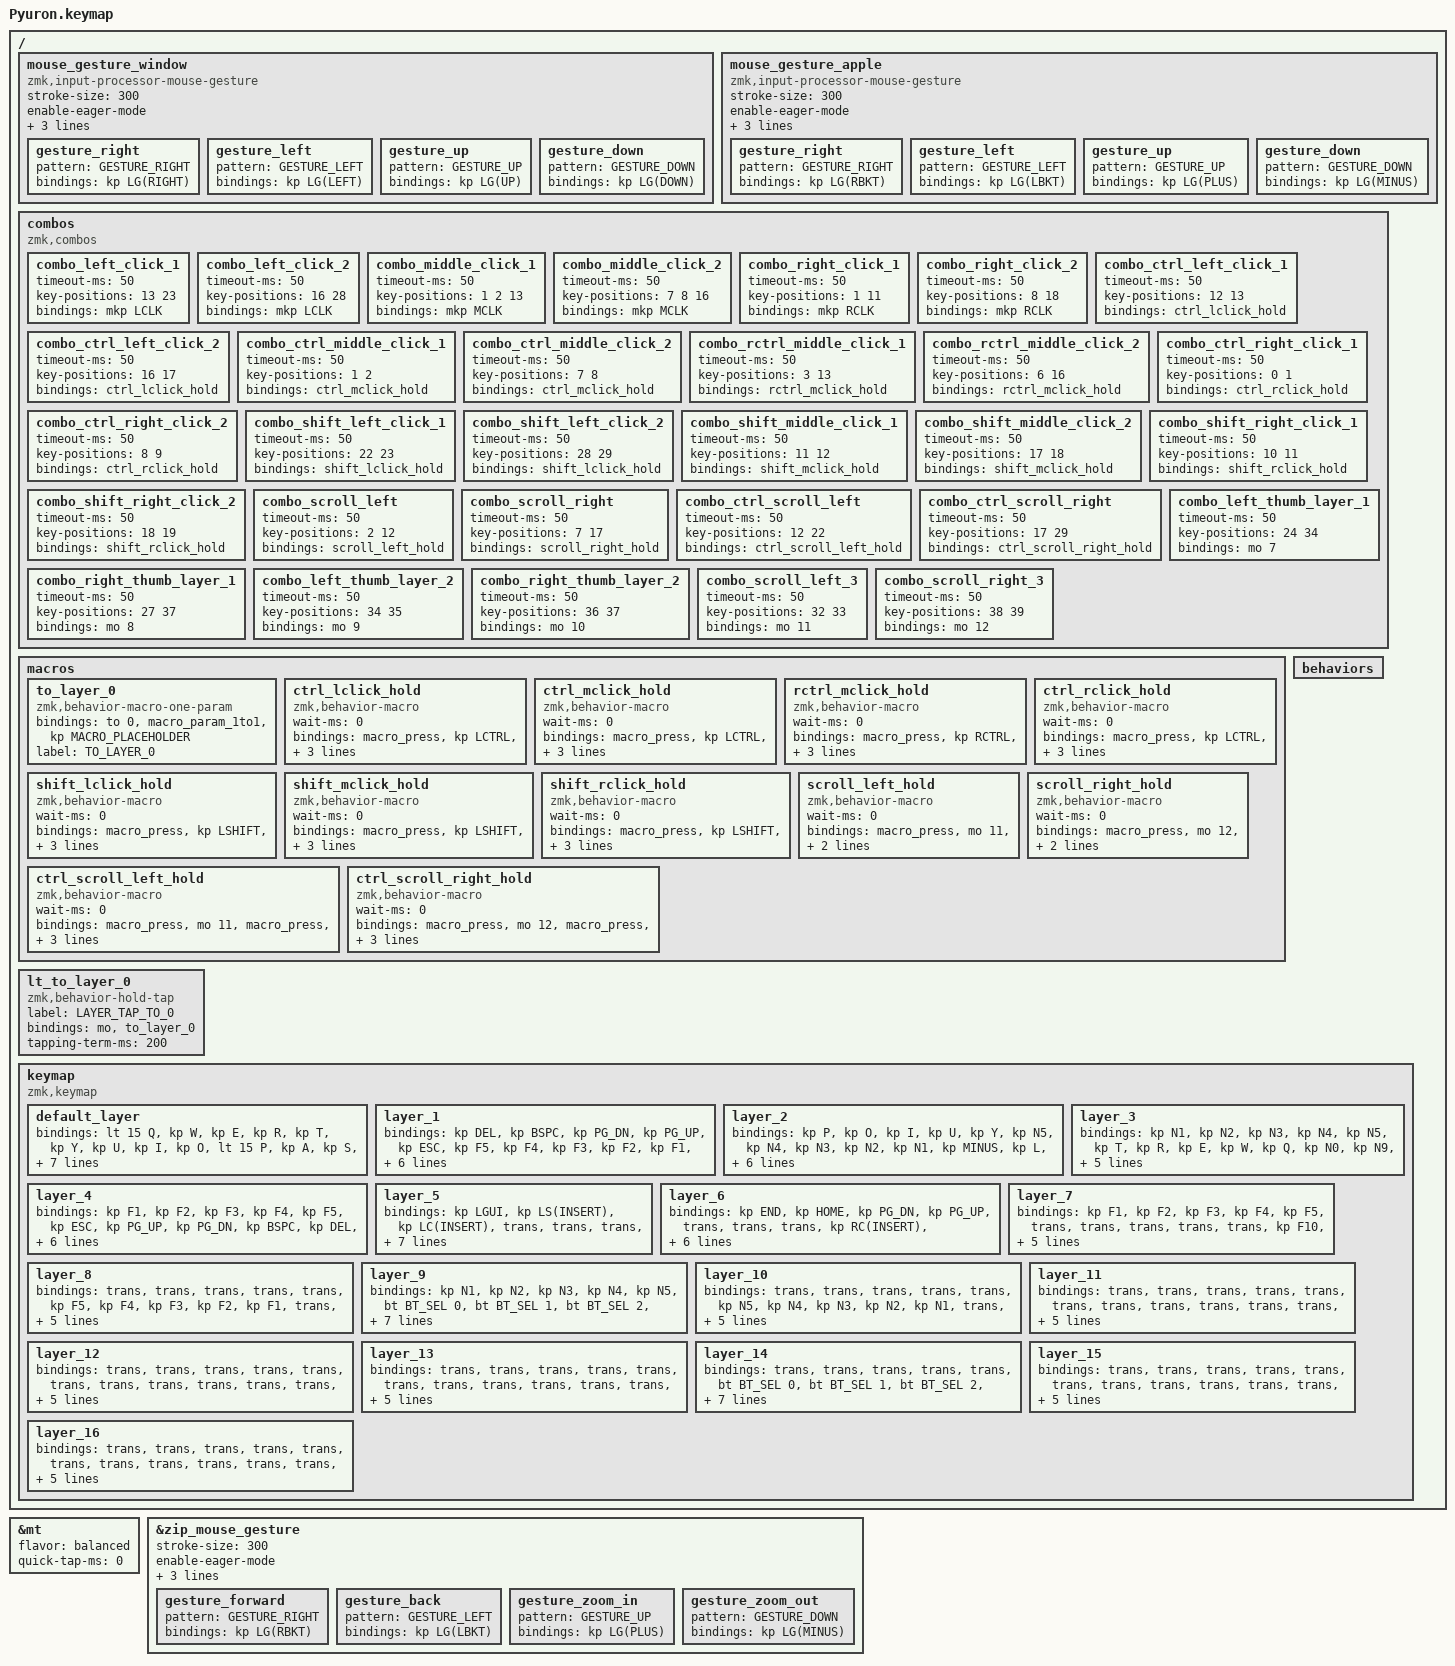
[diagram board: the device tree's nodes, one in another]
#include <behaviors.dtsi>
#include <dt-bindings/zmk/bt.h>
#include <dt-bindings/zmk/keys.h>
#include <dt-bindings/zmk/pointing.h>
#include <mouse-gesture.dtsi>
#include <zephyr/dt-bindings/input/input-event-codes.h>
#include <input/processors.dtsi>


&mt {
    flavor = "balanced";
    quick-tap-ms = <0>;
};

&zip_mouse_gesture {
    stroke-size = <300>;
    enable-eager-mode;
    suppress-movement;
    idle-timeout-ms = <150>;
    gesture-cooldown-ms = <500>;

    gesture_forward {
        pattern = <GESTURE_RIGHT>;
        bindings = <&kp LG(RBKT)>;
    };

    gesture_back {
        pattern = <GESTURE_LEFT>;
        bindings = <&kp LG(LBKT)>;
    };

    gesture_zoom_in {
        pattern = <GESTURE_UP>;
        bindings = <&kp LG(PLUS)>;
    };

    gesture_zoom_out {
        pattern = <GESTURE_DOWN>;
        bindings = <&kp LG(MINUS)>;
    };
};



/ {
mouse_gesture_window: mouse_gesture_window {
    compatible = "zmk,input-processor-mouse-gesture";
    #input-processor-cells = <0>;

    stroke-size = <300>;
    enable-eager-mode;
    suppress-movement;
    idle-timeout-ms = <150>;
    gesture-cooldown-ms = <500>;

    gesture_right {
        pattern = <GESTURE_RIGHT>;
        bindings = <&kp LG(RIGHT)>;
    };

    gesture_left {
        pattern = <GESTURE_LEFT>;
        bindings = <&kp LG(LEFT)>;
    };

    gesture_up {
        pattern = <GESTURE_UP>;
        bindings = <&kp LG(UP)>;
    };

    gesture_down {
        pattern = <GESTURE_DOWN>;
        bindings = <&kp LG(DOWN)>;
    };
};

mouse_gesture_apple: mouse_gesture_apple {
    compatible = "zmk,input-processor-mouse-gesture";
    #input-processor-cells = <0>;

    stroke-size = <300>;
    enable-eager-mode;
    suppress-movement;
    idle-timeout-ms = <150>;
    gesture-cooldown-ms = <500>;

    gesture_right {
        pattern = <GESTURE_RIGHT>;
        bindings = <&kp LG(RBKT)>;
    };

    gesture_left {
        pattern = <GESTURE_LEFT>;
        bindings = <&kp LG(LBKT)>;
    };

    gesture_up {
        pattern = <GESTURE_UP>;
        bindings = <&kp LG(PLUS)>;
    };

    gesture_down {
        pattern = <GESTURE_DOWN>;
        bindings = <&kp LG(MINUS)>;
    };
};


    combos {
    compatible = "zmk,combos";

    // ========================================
    // Normal mouse click
    // ========================================

    // Left click
    combo_left_click_1 {
        timeout-ms = <50>;
        key-positions = <13 23>;
        bindings = <&mkp LCLK>;
    };

    combo_left_click_2 {
        timeout-ms = <50>;
        key-positions = <16 28>;
        bindings = <&mkp LCLK>;
    };


    // Middle click
    combo_middle_click_1 {
        timeout-ms = <50>;
        key-positions = <1 2 13>;
        bindings = <&mkp MCLK>;
    };

    combo_middle_click_2 {
        timeout-ms = <50>;
        key-positions = <7 8 16>;
        bindings = <&mkp MCLK>;
    };


    // Right click
    combo_right_click_1 {
        timeout-ms = <50>;
        key-positions = <1 11>;
        bindings = <&mkp RCLK>;
    };

    combo_right_click_2 {
        timeout-ms = <50>;
        key-positions = <8 18>;
        bindings = <&mkp RCLK>;
    };


    // ========================================
    // Ctrl + mouse click
    // ========================================

    // Ctrl + Left click
    combo_ctrl_left_click_1 {
        timeout-ms = <50>;
        key-positions = <12 13>;
        bindings = <&ctrl_lclick_hold>;
    };

    combo_ctrl_left_click_2 {
        timeout-ms = <50>;
        key-positions = <16 17>;
        bindings = <&ctrl_lclick_hold>;
    };


    // Ctrl + Middle click
    combo_ctrl_middle_click_1 {
        timeout-ms = <50>;
        key-positions = <1 2>;
        bindings = <&ctrl_mclick_hold>;
    };

    combo_ctrl_middle_click_2 {
        timeout-ms = <50>;
        key-positions = <7 8>;
        bindings = <&ctrl_mclick_hold>;
    };

    // RCtrl + Middle click
    combo_rctrl_middle_click_1 {
        timeout-ms = <50>;
        key-positions = <3 13>;
        bindings = <&rctrl_mclick_hold>;
    };

    combo_rctrl_middle_click_2 {
        timeout-ms = <50>;
        key-positions = <6 16>;
        bindings = <&rctrl_mclick_hold>;
    };



    // Ctrl + Right click
    combo_ctrl_right_click_1 {
        timeout-ms = <50>;
        key-positions = <0 1>;
        bindings = <&ctrl_rclick_hold>;
    };

    combo_ctrl_right_click_2 {
        timeout-ms = <50>;
        key-positions = <8 9>;
        bindings = <&ctrl_rclick_hold>;
    };


    // ========================================
    // Shift + mouse click
    // ========================================

    // Shift + Left click
    combo_shift_left_click_1 {
        timeout-ms = <50>;
        key-positions = <22 23>;
        bindings = <&shift_lclick_hold>;
    };

    combo_shift_left_click_2 {
        timeout-ms = <50>;
        key-positions = <28 29>;
        bindings = <&shift_lclick_hold>;
    };


    // Shift + Middle click
    combo_shift_middle_click_1 {
        timeout-ms = <50>;
        key-positions = <11 12>;
        bindings = <&shift_mclick_hold>;
    };

    combo_shift_middle_click_2 {
        timeout-ms = <50>;
        key-positions = <17 18>;
        bindings = <&shift_mclick_hold>;
    };


    // Shift + Right click
    combo_shift_right_click_1 {
        timeout-ms = <50>;
        key-positions = <10 11>;
        bindings = <&shift_rclick_hold>;
    };

    combo_shift_right_click_2 {
        timeout-ms = <50>;
        key-positions = <18 19>;
        bindings = <&shift_rclick_hold>;
    };


    // ========================================
    // Normal scroll
    // ========================================

    // Left trackball scroll
    combo_scroll_left {
        timeout-ms = <50>;
        key-positions = <2 12>;
        bindings = <&scroll_left_hold>;
    };

    // Right trackball scroll
    combo_scroll_right {
        timeout-ms = <50>;
        key-positions = <7 17>;
        bindings = <&scroll_right_hold>;
    };


    // ========================================
    // Ctrl + scroll
    // ========================================

    // Left trackball Ctrl + scroll
    combo_ctrl_scroll_left {
        timeout-ms = <50>;
        key-positions = <12 22>;
        bindings = <&ctrl_scroll_left_hold>;
    };

    // Right trackball Ctrl + scroll
    combo_ctrl_scroll_right {
        timeout-ms = <50>;
        key-positions = <17 29>;
        bindings = <&ctrl_scroll_right_hold>;
    };


        // 左親指2キー → レイヤー7
        combo_left_thumb_layer_1 {
            timeout-ms = <50>;
            key-positions = <24 34>;
            bindings = <&mo 7>;
        };

        // 右親指2キー → レイヤー8
        combo_right_thumb_layer_1 {
            timeout-ms = <50>;
            key-positions = <27 37>;
            bindings = <&mo 8>;
        };

        // 左親指2キー → レイヤー9
        combo_left_thumb_layer_2 {
            timeout-ms = <50>;
            key-positions = <34 35>;
            bindings = <&mo 9>;
        };

        // 右親指2キー → レイヤー10
        combo_right_thumb_layer_2 {
            timeout-ms = <50>;
            key-positions = <36 37>;
            bindings = <&mo 10>;
        };


        // 左下外側2キー → 左トラックボールをスクロール
        combo_scroll_left_3 {
            timeout-ms = <50>;
            key-positions = <32 33>;
            bindings = <&mo 11>;
        };

        // 右下外側2キー → 右トラックボールをスクロール
        combo_scroll_right_3 {
            timeout-ms = <50>;
            key-positions = <38 39>;
            bindings = <&mo 12>;
        };
    };

    macros {
        to_layer_0: to_layer_0 {
            compatible = "zmk,behavior-macro-one-param";
            #binding-cells = <1>;
            bindings = <&to 0 &macro_param_1to1 &kp MACRO_PLACEHOLDER>;
            label = "TO_LAYER_0";
        };

    // ========================================
    // Ctrl + mouse click
    // ========================================

    ctrl_lclick_hold: ctrl_lclick_hold {
        compatible = "zmk,behavior-macro";
        #binding-cells = <0>;
        wait-ms = <0>;
        bindings =
            <&macro_press &kp LCTRL>,
            <&macro_wait_time 30>,
            <&macro_press &mkp MB1>,
            <&macro_pause_for_release>,
            <&macro_release &mkp MB1>,
            <&macro_release &kp LCTRL>;
    };

    ctrl_mclick_hold: ctrl_mclick_hold {
        compatible = "zmk,behavior-macro";
        #binding-cells = <0>;
        wait-ms = <0>;
        bindings =
            <&macro_press &kp LCTRL>,
            <&macro_wait_time 30>,
            <&macro_press &mkp MB2>,
            <&macro_pause_for_release>,
            <&macro_release &mkp MB2>,
            <&macro_release &kp LCTRL>;
    };

    rctrl_mclick_hold: rctrl_mclick_hold {
        compatible = "zmk,behavior-macro";
        #binding-cells = <0>;
        wait-ms = <0>;
        bindings =
            <&macro_press &kp RCTRL>,
            <&macro_wait_time 30>,
            <&macro_press &mkp MB2>,
            <&macro_pause_for_release>,
            <&macro_release &mkp MB2>,
            <&macro_release &kp RCTRL>;
    };

    ctrl_rclick_hold: ctrl_rclick_hold {
        compatible = "zmk,behavior-macro";
        #binding-cells = <0>;
        wait-ms = <0>;
        bindings =
            <&macro_press &kp LCTRL>,
            <&macro_wait_time 30>,
            <&macro_press &mkp MB3>,
            <&macro_pause_for_release>,
            <&macro_release &mkp MB3>,
            <&macro_release &kp LCTRL>;
    };


    // ========================================
    // Shift + mouse click
    // ========================================

    shift_lclick_hold: shift_lclick_hold {
        compatible = "zmk,behavior-macro";
        #binding-cells = <0>;
        wait-ms = <0>;
        bindings =
            <&macro_press &kp LSHIFT>,
            <&macro_wait_time 30>,
            <&macro_press &mkp MB1>,
            <&macro_pause_for_release>,
            <&macro_release &mkp MB1>,
            <&macro_release &kp LSHIFT>;
    };

    shift_mclick_hold: shift_mclick_hold {
        compatible = "zmk,behavior-macro";
        #binding-cells = <0>;
        wait-ms = <0>;
        bindings =
            <&macro_press &kp LSHIFT>,
            <&macro_wait_time 30>,
            <&macro_press &mkp MB2>,
            <&macro_pause_for_release>,
            <&macro_release &mkp MB2>,
            <&macro_release &kp LSHIFT>;
    };

    shift_rclick_hold: shift_rclick_hold {
        compatible = "zmk,behavior-macro";
        #binding-cells = <0>;
        wait-ms = <0>;
        bindings =
            <&macro_press &kp LSHIFT>,
            <&macro_wait_time 30>,
            <&macro_press &mkp MB3>,
            <&macro_pause_for_release>,
            <&macro_release &mkp MB3>,
            <&macro_release &kp LSHIFT>;
    };


    // ========================================
    // Normal scroll
    // Left trackball  -> Layer 11
    // Right trackball -> Layer 12
    // ========================================

    scroll_left_hold: scroll_left_hold {
        compatible = "zmk,behavior-macro";
        #binding-cells = <0>;
        wait-ms = <0>;
        bindings =
            <&macro_press &mo 11>,
            <&macro_pause_for_release>,
            <&macro_release &mo 11>;
    };

    scroll_right_hold: scroll_right_hold {
        compatible = "zmk,behavior-macro";
        #binding-cells = <0>;
        wait-ms = <0>;
        bindings =
            <&macro_press &mo 12>,
            <&macro_pause_for_release>,
            <&macro_release &mo 12>;
    };


    // ========================================
    // Ctrl + scroll
    // Left trackball  -> Layer 11 + Ctrl
    // Right trackball -> Layer 12 + Ctrl
    // ========================================

    ctrl_scroll_left_hold: ctrl_scroll_left_hold {
        compatible = "zmk,behavior-macro";
        #binding-cells = <0>;
        wait-ms = <0>;
        bindings =
            <&macro_press &mo 11>,
            <&macro_press &kp LCTRL>,
            <&macro_pause_for_release>,
            <&macro_release &kp LCTRL>,
            <&macro_release &mo 11>;
    };

    ctrl_scroll_right_hold: ctrl_scroll_right_hold {
        compatible = "zmk,behavior-macro";
        #binding-cells = <0>;
        wait-ms = <0>;
        bindings =
            <&macro_press &mo 12>,
            <&macro_press &kp LCTRL>,
            <&macro_pause_for_release>,
            <&macro_release &kp LCTRL>,
            <&macro_release &mo 12>;
    };


    };

    lt_to_layer_0: lt_to_layer_0 {
        compatible = "zmk,behavior-hold-tap";
        label = "LAYER_TAP_TO_0";
        bindings = <&mo>, <&to_layer_0>;

        #binding-cells = <2>;
        tapping-term-ms = <200>;
    };
};

/ {
    behaviors {
    };

    keymap {
        compatible = "zmk,keymap";

        default_layer {
            bindings = <

            // 物理行1: 0 - 9
            &lt 15 Q
            &kp W
            &kp E
            &kp R
            &kp T
            &kp Y
            &kp U
            &kp I
            &kp O
            &lt 15 P

            // 物理行2: 10 - 19
            &kp A
            &kp S
            &kp D
            &lt 5 F
            &mt LCTRL G
            &mt RCTRL H
            &lt 6 J
            &kp K
            &kp L
            &kp MINUS

            // 物理行3: 20 - 31
            &mt LSHFT Z
            &mt LALT X
            &mt LGUI C
            &mt LSHFT V
            &lt 4 B
            &lt 3 GRAVE
            &lt 2 GRAVE
            &lt 1 N
            &mt RSHFT M
            &mt RGUI COMMA
            &mt RALT DOT
            &mt RSHFT SLASH

            // 物理行4: 32 - 39
            &lt 16 ESC
            &mkp MB1
            &lt 1 SPACE
            &lt 2 ENTER
            &lt 3 ENTER
            &lt 4 SPACE
            &mkp MB1
            &lt 16 ESC

            >;
        };

        layer_1 {
            bindings = <

            // 物理行1: 0 - 9
            &kp DEL
            &kp BSPC
            &kp PG_DN
            &kp PG_UP
            &kp ESC
            &kp F5
            &kp F4
            &kp F3
            &kp F2
            &kp F1

            // 物理行2: 10 - 19
            &kp LCTRL
            &kp LEFT
            &kp UP
            &kp DOWN
            &kp RIGHT
            &kp F6
            &kp F7
            &kp F8
            &kp F9
            &kp F10

            // 物理行3: 20 - 31
            &kp LALT
            &kp TAB
            &kp END
            &kp HOME
            &kp LBKT
            &kp RBKT
            &trans
            &trans
            &trans
            &trans
            &kp F12
            &kp F11

            // 物理行4: 32 - 39
            &kp EQUAL
            &kp MINUS
            &trans
            &kp LGUI
            &kp SPACE
            &kp ENTER
            &trans
            &trans

            >;
        };

        layer_2 {
            bindings = <

            // 物理行1: 0 - 9
            &kp P
            &kp O
            &kp I
            &kp U
            &kp Y
            &kp N5
            &kp N4
            &kp N3
            &kp N2
            &kp N1

            // 物理行2: 10 - 19
            &kp MINUS
            &kp L
            &kp K
            &kp J
            &kp H
            &kp N6
            &kp N7
            &kp N8
            &kp N9
            &kp N0

            // 物理行3: 20 - 31
            &kp FSLH
            &kp DOT
            &kp COMMA
            &kp M
            &kp N
            &kp LSHFT
            &trans
            &kp SEMI
            &kp SQT
            &kp BSLH
            &kp LBKT
            &kp RBKT

            // 物理行4: 32 - 39
            &trans
            &trans
            &trans
            &trans
            &kp RSHFT
            &trans
            &trans
            &trans

            >;
        };

        layer_3 {
            bindings = <

            // 物理行1: 0 - 9
            &kp N1
            &kp N2
            &kp N3
            &kp N4
            &kp N5
            &kp T
            &kp R
            &kp E
            &kp W
            &kp Q

            // 物理行2: 10 - 19
            &kp N0
            &kp N9
            &kp N8
            &kp N7
            &kp N6
            &kp G
            &kp F
            &kp D
            &kp S
            &kp A

            // 物理行3: 20 - 31
            &kp LBKT
            &kp RBKT
            &kp BSLH
            &kp SQT
            &kp SEMI
            &trans
            &kp RSHFT
            &kp B
            &kp V
            &kp C
            &kp X
            &kp Z

            // 物理行4: 32 - 39
            &trans
            &trans
            &trans
            &kp LSHFT
            &trans
            &trans
            &trans
            &trans

            >;
        };

        layer_4 {
            bindings = <

            // 物理行1: 0 - 9
            &kp F1
            &kp F2
            &kp F3
            &kp F4
            &kp F5
            &kp ESC
            &kp PG_UP
            &kp PG_DN
            &kp BSPC
            &kp DEL

            // 物理行2: 10 - 19
            &kp F10
            &kp F9
            &kp F8
            &kp F7
            &kp F6
            &kp LEFT
            &kp DOWN
            &kp UP
            &kp RIGHT
            &kp RCTRL

            // 物理行3: 20 - 31
            &kp F11
            &kp F12
            &trans
            &trans
            &trans
            &trans
            &kp LBKT
            &kp RBKT
            &kp HOME
            &kp END
            &kp TAB
            &kp RALT

            // 物理行4: 32 - 39
            &trans
            &trans
            &kp ENTER
            &kp SPACE
            &kp RGUI
            &trans
            &kp MINUS
            &kp EQUAL

            >;
        };

        layer_5 {
            bindings = <

            // 物理行1: 0 - 9
            &kp LGUI
            &kp LS(INSERT)
            &kp LC(INSERT)
            &trans
            &trans
            &trans
            &kp PG_UP
            &kp PG_DN
            &kp HOME
            &kp END

            // 物理行2: 10 - 19
            &kp ESC
            &kp RCTRL
            &kp LCTRL
            &trans
            &trans
            &trans
            &mkp MB1
            &mkp MB2
            &mkp MB3
            &kp ESC

            // 物理行3: 20 - 31
            &trans
            &trans
            &trans
            &trans
            &trans
            &trans
            &trans
            &trans
            &trans
            &trans
            &trans
            &trans

            // 物理行4: 32 - 39
            &trans
            &mkp MB2
            &trans
            &trans
            &trans
            &trans
            &trans
            &trans

            >;
        };

        layer_6 {
            bindings = <

            // 物理行1: 0 - 9
            &kp END
            &kp HOME
            &kp PG_DN
            &kp PG_UP
            &trans
            &trans
            &trans
            &kp RC(INSERT)
            &kp RS(INSERT)
            &kp RGUI

            // 物理行2: 10 - 19
            &kp ESC
            &mkp MB3
            &mkp MB2
            &mkp MB1
            &trans
            &trans
            &trans
            &kp LCTRL
            &kp RCTRL
            &kp ESC

            // 物理行3: 20 - 31
            &trans
            &trans
            &trans
            &trans
            &trans
            &trans
            &trans
            &trans
            &trans
            &trans
            &trans
            &trans

            // 物理行4: 32 - 39
            &trans
            &trans
            &trans
            &trans
            &trans
            &trans
            &trans
            &trans

            >;
        };

        layer_7 {
            bindings = <

            // 物理行1: 0 - 9
            &kp F1
            &kp F2
            &kp F3
            &kp F4
            &kp F5
            &trans
            &trans
            &trans
            &trans
            &trans

            // 物理行2: 10 - 19
            &kp F10
            &kp F9
            &kp F8
            &kp F7
            &kp F6
            &trans
            &trans
            &trans
            &trans
            &trans

            // 物理行3: 20 - 31
            &kp F11
            &kp F12
            &trans
            &trans
            &trans
            &trans
            &trans
            &trans
            &trans
            &trans
            &trans
            &trans

            // 物理行4: 32 - 39
            &trans
            &trans
            &trans
            &trans
            &trans
            &trans
            &trans
            &trans

            >;
        };

        layer_8 {
            bindings = <

            // 物理行1: 0 - 9
            &trans
            &trans
            &trans
            &trans
            &trans
            &kp F5
            &kp F4
            &kp F3
            &kp F2
            &kp F1

            // 物理行2: 10 - 19
            &trans
            &trans
            &trans
            &trans
            &trans
            &kp F6
            &kp F7
            &kp F8
            &kp F9
            &kp F10

            // 物理行3: 20 - 31
            &trans
            &trans
            &trans
            &trans
            &trans
            &trans
            &trans
            &trans
            &trans
            &trans
            &kp F12
            &kp F11

            // 物理行4: 32 - 39
            &trans
            &trans
            &trans
            &trans
            &trans
            &trans
            &trans
            &trans

            >;
        };

        layer_9 {
            bindings = <

            // 物理行1: 0 - 9
            &kp N1
            &kp N2
            &kp N3
            &kp N4
            &kp N5
            &bt BT_SEL 0
            &bt BT_SEL 1
            &bt BT_SEL 2
            &bt BT_SEL 3
            &bt BT_SEL 4

            // 物理行2: 10 - 19
            &kp N0
            &kp N9
            &kp N8
            &kp N7
            &kp N6
            &trans
            &trans
            &trans
            &trans
            &trans

            // 物理行3: 20 - 31
            &trans
            &trans
            &trans
            &trans
            &trans
            &trans
            &bootloader
            &trans
            &trans
            &trans
            &trans
            &trans

            // 物理行4: 32 - 39
            &trans
            &bt BT_CLR
            &trans
            &trans
            &trans
            &trans
            &trans
            &bt BT_CLR_ALL

            >;
        };

        layer_10 {
            bindings = <

            // 物理行1: 0 - 9
            &trans
            &trans
            &trans
            &trans
            &trans
            &kp N5
            &kp N4
            &kp N3
            &kp N2
            &kp N1

            // 物理行2: 10 - 19
            &trans
            &trans
            &trans
            &trans
            &trans
            &kp N6
            &kp N7
            &kp N8
            &kp N9
            &kp N0

            // 物理行3: 20 - 31
            &trans
            &trans
            &trans
            &trans
            &trans
            &trans
            &trans
            &trans
            &trans
            &trans
            &trans
            &trans

            // 物理行4: 32 - 39
            &trans
            &trans
            &trans
            &trans
            &trans
            &trans
            &trans
            &trans

            >;
        };

        layer_11 {
            bindings = <

            // 物理行1: 0 - 9
            &trans
            &trans
            &trans
            &trans
            &trans
            &trans
            &trans
            &trans
            &trans
            &trans

            // 物理行2: 10 - 19
            &trans
            &trans
            &trans
            &trans
            &trans
            &trans
            &trans
            &trans
            &trans
            &trans

            // 物理行3: 20 - 31
            &trans
            &trans
            &trans
            &trans
            &trans
            &trans
            &trans
            &trans
            &trans
            &trans
            &trans
            &trans

            // 物理行4: 32 - 39
            &trans
            &trans
            &trans
            &trans
            &trans
            &trans
            &trans
            &trans

            >;
        };

        layer_12 {
            bindings = <

            // 物理行1: 0 - 9
            &trans
            &trans
            &trans
            &trans
            &trans
            &trans
            &trans
            &trans
            &trans
            &trans

            // 物理行2: 10 - 19
            &trans
            &trans
            &trans
            &trans
            &trans
            &trans
            &trans
            &trans
            &trans
            &trans

            // 物理行3: 20 - 31
            &trans
            &trans
            &trans
            &trans
            &trans
            &trans
            &trans
            &trans
            &trans
            &trans
            &trans
            &trans

            // 物理行4: 32 - 39
            &trans
            &trans
            &trans
            &trans
            &trans
            &trans
            &trans
            &trans

            >;
        };

        layer_13 {
            bindings = <

            // 物理行1: 0 - 9
            &trans
            &trans
            &trans
            &trans
            &trans
            &trans
            &trans
            &trans
            &trans
            &trans

            // 物理行2: 10 - 19
            &trans
            &trans
            &trans
            &trans
            &trans
            &trans
            &trans
            &trans
            &trans
            &trans

            // 物理行3: 20 - 31
            &trans
            &trans
            &trans
            &trans
            &trans
            &trans
            &trans
            &trans
            &trans
            &trans
            &trans
            &trans

            // 物理行4: 32 - 39
            &trans
            &trans
            &trans
            &trans
            &trans
            &trans
            &trans
            &trans

            >;
        };

        layer_14 {
            bindings = <

            // 物理行1: 0 - 9
            &trans
            &trans
            &trans
            &trans
            &trans
            &bt BT_SEL 0
            &bt BT_SEL 1
            &bt BT_SEL 2
            &bt BT_SEL 3
            &bt BT_SEL 4

            // 物理行2: 10 - 19
            &trans
            &trans
            &trans
            &trans
            &trans
            &trans
            &trans
            &trans
            &trans
            &trans

            // 物理行3: 20 - 31
            &trans
            &trans
            &trans
            &trans
            &trans
            &trans
            &bootloader
            &trans
            &trans
            &trans
            &trans
            &trans

            // 物理行4: 32 - 39
            &trans
            &bt BT_CLR
            &trans
            &trans
            &trans
            &trans
            &trans
            &bt BT_CLR_ALL

            >;
        };

        layer_15 {
            bindings = <

            // 物理行1: 0 - 9
            &trans
            &trans
            &trans
            &trans
            &trans
            &trans
            &trans
            &trans
            &trans
            &trans

            // 物理行2: 10 - 19
            &trans
            &trans
            &trans
            &trans
            &trans
            &trans
            &trans
            &trans
            &trans
            &trans

            // 物理行3: 20 - 31
            &trans
            &trans
            &trans
            &trans
            &trans
            &trans
            &trans
            &trans
            &trans
            &trans
            &trans
            &trans

            // 物理行4: 32 - 39
            &trans
            &trans
            &trans
            &trans
            &trans
            &trans
            &trans
            &trans

            >;
        };

        layer_16 {
            bindings = <

            // 物理行1: 0 - 9
            &trans
            &trans
            &trans
            &trans
            &trans
            &trans
            &trans
            &trans
            &trans
            &trans

            // 物理行2: 10 - 19
            &trans
            &trans
            &trans
            &trans
            &trans
            &trans
            &trans
            &trans
            &trans
            &trans

            // 物理行3: 20 - 31
            &trans
            &trans
            &trans
            &trans
            &trans
            &trans
            &trans
            &trans
            &trans
            &trans
            &trans
            &trans

            // 物理行4: 32 - 39
            &trans
            &mkp MB2
            &trans
            &trans
            &trans
            &trans
            &mkp MB2
            &trans

            >;
        };

    };
};
